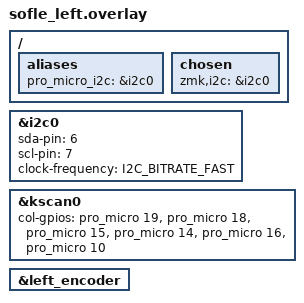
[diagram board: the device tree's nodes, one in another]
/*
 * Copyright (c) 2020 Ryan Cross
 *
 * SPDX-License-Identifier: MIT
 */

#include "sofle.dtsi"

/ {
    aliases {
        pro_micro_i2c = &i2c0;
    };

    chosen {
        zmk,i2c = &i2c0;
    };
};

&i2c0 {
    status = "okay";
    sda-pin = <6>;  /* P0.06 for SDA on nice_nano_v2 */
    scl-pin = <7>;  /* P0.07 for SCL on nice_nano_v2 */
    clock-frequency = <I2C_BITRATE_FAST>;
};

&kscan0 {
    col-gpios
        = <&pro_micro 19 GPIO_ACTIVE_HIGH>
        , <&pro_micro 18 GPIO_ACTIVE_HIGH>
        , <&pro_micro 15 GPIO_ACTIVE_HIGH>
        , <&pro_micro 14 GPIO_ACTIVE_HIGH>
        , <&pro_micro 16 GPIO_ACTIVE_HIGH>
        , <&pro_micro 10 GPIO_ACTIVE_HIGH>
        ;
};

&left_encoder {
    status = "okay";
};
